# ESP32-S3-ULP register map
Vendor: ESPRESSIF SYSTEMS (SHANGHAI) CO., LTD.; Series: RISC-V ULP; File version: 1
CPU: RV32IMC r0p0, little endian, no MPU, no FPU, 4 interrupt priority bits
Address unit: 32 bits
Registers are 32-bit, read-write, reset 0x0 unless marked. A register's access mark holds for its fields unless they carry their own. Offsets are from the block's base; [hi:lo] are bit positions; {n}, {i} and the like mark numbered series.

## SENS — SENS Peripheral
Base 0x0000C800
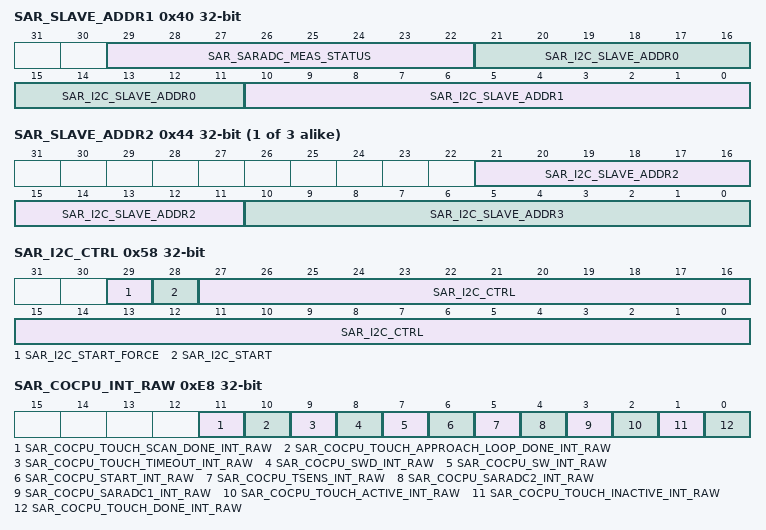
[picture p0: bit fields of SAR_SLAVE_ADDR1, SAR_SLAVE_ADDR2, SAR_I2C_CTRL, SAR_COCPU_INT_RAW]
0x40 SAR_SLAVE_ADDR1 access per field — configure i2c slave address
  [29:22] SAR_SARADC_MEAS_STATUS ro — no public
  [21:11] SAR_I2C_SLAVE_ADDR0 rw — configure i2c slave address0
  [10:0] SAR_I2C_SLAVE_ADDR1 rw — configure i2c slave address1
{0x3C+4i} SAR_SLAVE_ADDR{i} (i=2..4) — configure i2c slave address
  [21:11] SAR_I2C_SLAVE_ADDR{2i-2} — configure i2c slave address{2i-2}
  [10:0] SAR_I2C_SLAVE_ADDR{2i-1} — configure i2c slave address{2i-1}
0x58 SAR_I2C_CTRL — configure rtc i2c controller by sw
  [29] SAR_I2C_START_FORCE — 1: I2C started by SW 0: I2C started by FSM
  [28] SAR_I2C_START — start I2C only active when reg_sar_i2c_start_force = 1
  [27:0] SAR_I2C_CTRL — I2C control data only active when reg_sar_i2c_start_force = 1
0xE8 SAR_COCPU_INT_RAW ro — the interrupt raw of ulp
  [11] SAR_COCPU_TOUCH_SCAN_DONE_INT_RAW — int from touch scan done
  [10] SAR_COCPU_TOUCH_APPROACH_LOOP_DONE_INT_RAW — int from approach loop done
  [9] SAR_COCPU_TOUCH_TIMEOUT_INT_RAW — int from timeout done
  [8] SAR_COCPU_SWD_INT_RAW — int from super watch dog
  [7] SAR_COCPU_SW_INT_RAW — int from software
  [6] SAR_COCPU_START_INT_RAW — int from start
  [5] SAR_COCPU_TSENS_INT_RAW — int from tsens
  [4] SAR_COCPU_SARADC2_INT_RAW — int from saradc2
  [3] SAR_COCPU_SARADC1_INT_RAW — int from saradc1
  [2] SAR_COCPU_TOUCH_ACTIVE_INT_RAW — int from touch active
  [1] SAR_COCPU_TOUCH_INACTIVE_INT_RAW — int from touch inactive
  [0] SAR_COCPU_TOUCH_DONE_INT_RAW — int from touch done
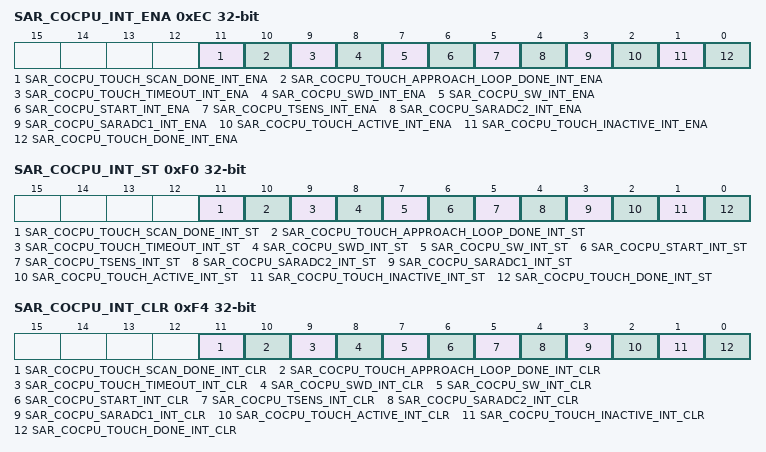
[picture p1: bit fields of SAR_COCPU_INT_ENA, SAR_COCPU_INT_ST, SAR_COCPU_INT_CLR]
0xEC SAR_COCPU_INT_ENA — the interrupt enable of ulp
  [11] SAR_COCPU_TOUCH_SCAN_DONE_INT_ENA — int enable of touch scan done
  [10] SAR_COCPU_TOUCH_APPROACH_LOOP_DONE_INT_ENA — int enable of approach loop done
  [9] SAR_COCPU_TOUCH_TIMEOUT_INT_ENA — int enable of timeout done
  [8] SAR_COCPU_SWD_INT_ENA — int enable of super watch dog
  [7] SAR_COCPU_SW_INT_ENA — int enable of software
  [6] SAR_COCPU_START_INT_ENA — int enable of start
  [5] SAR_COCPU_TSENS_INT_ENA — int enable of tsens
  [4] SAR_COCPU_SARADC2_INT_ENA — int enable of from saradc2
  [3] SAR_COCPU_SARADC1_INT_ENA — int enable of from saradc1
  [2] SAR_COCPU_TOUCH_ACTIVE_INT_ENA — int enable of touch active
  [1] SAR_COCPU_TOUCH_INACTIVE_INT_ENA — int enable of from touch inactive
  [0] SAR_COCPU_TOUCH_DONE_INT_ENA — int enable of touch done
0xF0 SAR_COCPU_INT_ST ro — the interrupt state of ulp
  [11] SAR_COCPU_TOUCH_SCAN_DONE_INT_ST — int state of touch scan done
  [10] SAR_COCPU_TOUCH_APPROACH_LOOP_DONE_INT_ST — int state of approach loop done
  [9] SAR_COCPU_TOUCH_TIMEOUT_INT_ST — int state of timeout done
  [8] SAR_COCPU_SWD_INT_ST — int state of super watch dog
  [7] SAR_COCPU_SW_INT_ST — int state of software
  [6] SAR_COCPU_START_INT_ST — int state of start
  [5] SAR_COCPU_TSENS_INT_ST — int state of tsens
  [4] SAR_COCPU_SARADC2_INT_ST — int state of from saradc2
  [3] SAR_COCPU_SARADC1_INT_ST — int state of from saradc1
  [2] SAR_COCPU_TOUCH_ACTIVE_INT_ST — int state of touch active
  [1] SAR_COCPU_TOUCH_INACTIVE_INT_ST — int state of from touch inactive
  [0] SAR_COCPU_TOUCH_DONE_INT_ST — int state of touch done
0xF4 SAR_COCPU_INT_CLR wo — the interrupt clear of ulp
  [11] SAR_COCPU_TOUCH_SCAN_DONE_INT_CLR — int clear of touch scan done
  [10] SAR_COCPU_TOUCH_APPROACH_LOOP_DONE_INT_CLR — int clear of approach loop done
  [9] SAR_COCPU_TOUCH_TIMEOUT_INT_CLR — int clear of timeout done
  [8] SAR_COCPU_SWD_INT_CLR — int clear of super watch dog
  [7] SAR_COCPU_SW_INT_CLR — int clear of software
  [6] SAR_COCPU_START_INT_CLR — int clear of start
  [5] SAR_COCPU_TSENS_INT_CLR — int clear of tsens
  [4] SAR_COCPU_SARADC2_INT_CLR — int clear of from saradc2
  [3] SAR_COCPU_SARADC1_INT_CLR — int clear of from saradc1
  [2] SAR_COCPU_TOUCH_ACTIVE_INT_CLR — int clear of touch active
  [1] SAR_COCPU_TOUCH_INACTIVE_INT_CLR — int clear of from touch inactive
  [0] SAR_COCPU_TOUCH_DONE_INT_CLR — int clear of touch done

## Notices in the file
Copyright 2023 Espressif Systems (Shanghai) PTE LTD
Licensed under the Apache License, Version 2.0 (the "License");
you may not use this file except in compliance with the License.
You may obtain a copy of the License at
http://www.apache.org/licenses/LICENSE-2.0
Unless required by applicable law or agreed to in writing, software
distributed under the License is distributed on an "AS IS" BASIS,
WITHOUT WARRANTIES OR CONDITIONS OF ANY KIND, either express or implied.
See the License for the specific language governing permissions and
limitations under the License.
